AUTOSAR XML (schema 4.0)
package /Powertrain_Components
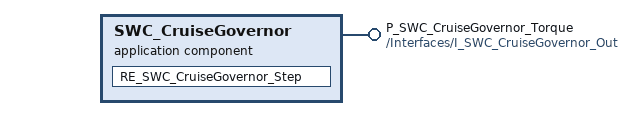
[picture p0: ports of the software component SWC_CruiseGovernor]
  application sw component type SWC_CruiseGovernor  # AUTOSAR Application SWC SWC_CruiseGovernor for Powertrain Control
    provide port P_SWC_CruiseGovernor_Torque: provided-interface=/Interfaces/I_SWC_CruiseGovernor_Out
    behavior SWC_CruiseGovernor_Behavior
      runnable RE_SWC_CruiseGovernor_Step: symbol=SWC_CruiseGovernor_Step
  sender receiver interface I_SWC_CruiseGovernor_Out
    data DE_SWC_CruiseGovernor_TorqueDemand: type=/AUTOSAR/Platform/uint32
